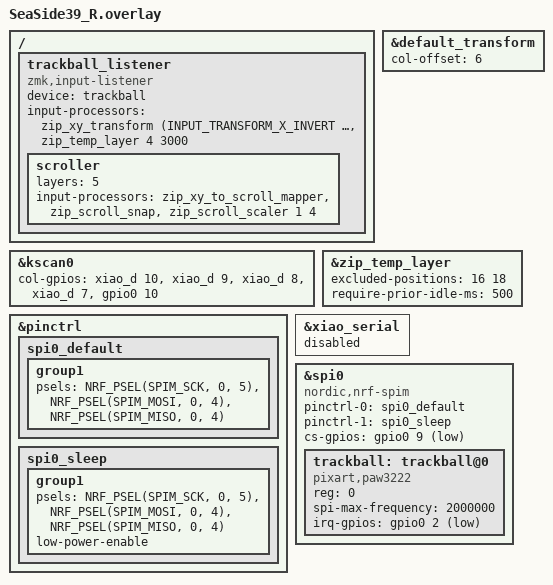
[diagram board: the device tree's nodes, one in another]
#include "SeaSide39.dtsi"
#include <input/processors.dtsi>
#include <dt-bindings/zmk/input_transform.h>
#include <scroll-snap.dtsi>

&default_transform {
    col-offset = <6>;
};

/* キーマトリクスの設定 */
&kscan0 {
        col-gpios
            = <&xiao_d 10 GPIO_ACTIVE_HIGH>
            , <&xiao_d 9 GPIO_ACTIVE_HIGH> 
            , <&xiao_d 8 GPIO_ACTIVE_HIGH> 
            , <&xiao_d 7 GPIO_ACTIVE_HIGH> 
            , <&gpio0 10 GPIO_ACTIVE_HIGH>
            ;
};

/* AML解除対象外のキー */ 

&zip_temp_layer {
    excluded-positions = <
        16 // 左クリック
        18 // 右クリック
/*
        17 // 上
        26 // 左
        27 // 下
        28 // 右
*/
    >;
};

/* キー入力後AML発動を抑制する時間 */ 
&zip_temp_layer {
    require-prior-idle-ms = <500>;
};

/* Trackball のリスナー */ 
/ {
    trackball_listener {
        compatible = "zmk,input-listener";
        device = <&trackball>;

/* input-processors設定 */ 
        input-processors = <
/* PAW3222用設定（カーソル移動方向反転） */ 
            &zip_xy_transform (INPUT_TRANSFORM_X_INVERT | INPUT_TRANSFORM_Y_INVERT)
/* AML発動条件設定 */ 
            &zip_temp_layer 4 3000
        >;

/* スクロールレイヤー設定 */
        scroller {
            layers = <5>;
            //input-processors = <&zip_xy_to_scroll_mapper>;
            input-processors = <
                &zip_xy_to_scroll_mapper
		        &zip_scroll_snap
                &zip_scroll_scaler 1 4
            >;
        };
    };
};

/* SPI 設定 */
&pinctrl {
    spi0_default: spi0_default {
        group1 {
            psels = <NRF_PSEL(SPIM_SCK, 0, 5)>,
                <NRF_PSEL(SPIM_MOSI, 0, 4)>,
                <NRF_PSEL(SPIM_MISO, 0, 4)>;
        };
    };

    spi0_sleep: spi0_sleep {
        group1 {
            psels = <NRF_PSEL(SPIM_SCK, 0, 5)>,
                <NRF_PSEL(SPIM_MOSI, 0, 4)>,
                <NRF_PSEL(SPIM_MISO, 0, 4)>;
            low-power-enable;
        };
    };
};

/* シリアルを無効化 */
&xiao_serial { status = "disabled"; };

/* SPI デバイス (トラックボール) */
&spi0 {
    status = "okay";
    compatible = "nordic,nrf-spim";
    pinctrl-0 = <&spi0_default>;
    pinctrl-1 = <&spi0_sleep>;
    pinctrl-names = "default", "sleep";
    cs-gpios = <&gpio0 9 GPIO_ACTIVE_LOW>;

    trackball: trackball@0 {
        status = "okay";
        //compatible = "pixart,pmw3610";
        compatible = "pixart,paw3222";
        reg = <0>;
        spi-max-frequency = <2000000>;
        irq-gpios = <&gpio0 2 (GPIO_ACTIVE_LOW | GPIO_PULL_UP)>;
        // automouse-layer = <4>; //ここをコメントアウトするとオートマウスレイヤーがオフになる
        //scroll-layers = <5>; //trackball-listenerで設定
    };
};

